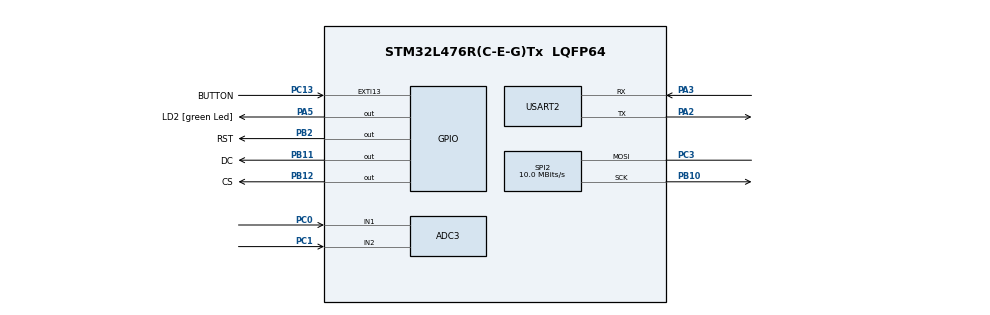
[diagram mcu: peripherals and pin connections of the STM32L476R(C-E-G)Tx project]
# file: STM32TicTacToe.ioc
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ADC3.Channel-0\#ChannelRegularConversion=ADC_CHANNEL_1
ADC3.Channel-1\#ChannelRegularConversion=ADC_CHANNEL_2
ADC3.ClockPrescaler=ADC_CLOCK_SYNC_PCLK_DIV4
ADC3.DataAlign=ADC_DATAALIGN_RIGHT
ADC3.NbrOfConversion=2
ADC3.NbrOfConversionFlag=1
ADC3.OffsetNumber-0\#ChannelRegularConversion=ADC_OFFSET_NONE
ADC3.OffsetNumber-1\#ChannelRegularConversion=ADC_OFFSET_NONE
ADC3.Rank-0\#ChannelRegularConversion=1
ADC3.Rank-1\#ChannelRegularConversion=2
ADC3.SamplingTime-0\#ChannelRegularConversion=ADC_SAMPLETIME_92CYCLES_5
ADC3.SamplingTime-1\#ChannelRegularConversion=ADC_SAMPLETIME_92CYCLES_5
Dma.Request0=SPI2_TX
Dma.SPI2_TX.0.Direction=DMA_MEMORY_TO_PERIPH
Dma.SPI2_TX.0.Instance=DMA1_Channel5
Dma.SPI2_TX.0.MemDataAlignment=DMA_MDATAALIGN_BYTE
Dma.SPI2_TX.0.MemInc=DMA_MINC_ENABLE
Dma.SPI2_TX.0.Mode=DMA_NORMAL
Dma.SPI2_TX.0.PeriphDataAlignment=DMA_PDATAALIGN_BYTE
Dma.SPI2_TX.0.PeriphInc=DMA_PINC_DISABLE
Dma.SPI2_TX.0.Priority=DMA_PRIORITY_LOW
Mcu.Family=STM32L4
Mcu.Name=STM32L476R(C-E-G)Tx
Mcu.Package=LQFP64
NVIC.DMA1_Channel5_IRQn=true\:0\:0\:false\:false\:true\:false\:true\:true
NVIC.EXTI15_10_IRQn=true\:0\:0\:false\:false\:true\:true\:true\:true
NVIC.PriorityGroup=NVIC_PRIORITYGROUP_4
PA13\ (JTMS-SWDIO).GPIO_Label=TMS
PA13\ (JTMS-SWDIO).Mode=Serial_Wire
PA13\ (JTMS-SWDIO).Signal=SYS_JTMS-SWDIO
PA14\ (JTCK-SWCLK).GPIO_Label=TCK
PA14\ (JTCK-SWCLK).Mode=Serial_Wire
PA14\ (JTCK-SWCLK).Signal=SYS_JTCK-SWCLK
PA2.Mode=Asynchronous
PA2.Signal=USART2_TX
PA3.Mode=Asynchronous
PA3.Signal=USART2_RX
PA5.GPIO_Label=LD2 [green Led]
PA5.GPIO_ModeDefaultOutputPP=GPIO_MODE_OUTPUT_PP
PA5.GPIO_PuPd=GPIO_NOPULL
PA5.GPIO_Speed=GPIO_SPEED_FREQ_LOW
PA5.Signal=GPIO_Output
PB10.Mode=Simplex_Bidirectional_Master
PB10.Signal=SPI2_SCK
PB11.GPIO_Label=DC
PB11.Signal=GPIO_Output
PB12.GPIO_Label=CS
PB12.PinState=GPIO_PIN_SET
PB12.Signal=GPIO_Output
PB2.GPIO_Label=RST
PB2.Signal=GPIO_Output
PB3\ (JTDO-TRACESWO).GPIO_Label=SWO
PB3\ (JTDO-TRACESWO).Signal=SYS_JTDO-SWO
PC0.Signal=ADCx_IN1
PC1.Signal=ADCx_IN2
PC13.GPIO_Label=BUTTON
PC13.GPIO_ModeDefaultEXTI=GPIO_MODE_IT_FALLING
PC13.GPIO_PuPd=GPIO_NOPULL
PC13.Signal=GPXTI13
PC14-OSC32_IN\ (PC14).Mode=LSE-External-Oscillator
PC14-OSC32_IN\ (PC14).Signal=RCC_OSC32_IN
PC15-OSC32_OUT\ (PC15).Mode=LSE-External-Oscillator
PC15-OSC32_OUT\ (PC15).Signal=RCC_OSC32_OUT
PC3.Mode=Simplex_Bidirectional_Master
PC3.Signal=SPI2_MOSI
PH0-OSC_IN\ (PH0).Signal=RCC_OSC_IN
PH1-OSC_OUT\ (PH1).Signal=RCC_OSC_OUT
ProjectManager.HeapSize=0x1500
ProjectManager.StackSize=0x2000
ProjectManager.TargetToolchain=STM32CubeIDE
RCC.ADCFreq_Value=64000000
RCC.AHBFreq_Value=80000000
RCC.APB1Freq_Value=80000000
RCC.APB1TimFreq_Value=80000000
RCC.APB2Freq_Value=80000000
RCC.APB2TimFreq_Value=80000000
RCC.CortexFreq_Value=80000000
RCC.HCLKFreq_Value=80000000
RCC.HSE_VALUE=8000000
RCC.HSI_VALUE=16000000
RCC.MSI_VALUE=4000000
RCC.PLLN=10
RCC.PLLSAI1Q=RCC_PLLQ_DIV4
RCC.PLLSourceVirtual=RCC_PLLSOURCE_HSI
RCC.PREFETCH_ENABLE=1
RCC.SYSCLKFreq_VALUE=80000000
RCC.SYSCLKSource=RCC_SYSCLKSOURCE_PLLCLK
RCC.USBFreq_Value=32000000
RCC.VCOOutputFreq_Value=160000000
SH.ADCx_IN1.0=ADC3_IN1,IN1-Single-Ended
SH.ADCx_IN2.0=ADC3_IN2,IN2-Single-Ended
SPI2.BaudRatePrescaler=SPI_BAUDRATEPRESCALER_8
SPI2.CalculateBaudRate=10.0 MBits/s
SPI2.DataSize=SPI_DATASIZE_8BIT
SPI2.Direction=SPI_DIRECTION_1LINE
SPI2.Mode=SPI_MODE_MASTER
SPI2.NSSPMode=SPI_NSS_PULSE_DISABLE
SPI2.VirtualType=VM_MASTER
USART2.VirtualMode-Asynchronous=VM_ASYNC
board=NUCLEO-L476RG

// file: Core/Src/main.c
/* USER CODE BEGIN Header */
/**
  ******************************************************************************
  * @file           : main.c
  * @brief          : Main program body
  ******************************************************************************
  * @attention
  *
  * Copyright (c) 2024 STMicroelectronics.
  * All rights reserved.
  *
  * This software is licensed under terms that can be found in the LICENSE file
  * in the root directory of this software component.
  * If no LICENSE file comes with this software, it is provided AS-IS.
  *
  ******************************************************************************
  */
/* USER CODE END Header */
#include "main.h"
#include "adc.h"
#include "dma.h"
#include "spi.h"
#include "usart.h"
#include "gpio.h"

/* USER CODE BEGIN Includes */
#include "../MyLibraries/ADC.h"
#include "../MyLibraries/GPIO.h"
#include "../MyLibraries/LCD.h"
#include "../MyLibraries/SPI.h"
#include "../MyLibraries/TICTACTOE.h"
#include "../MyLibraries/USART.h"
#include <stdio.h>
/* USER CODE END Includes */

void SystemClock_Config(void);

int main(void)
{

  /* MCU Configuration--------------------------------------------------------*/

  /* Reset of all peripherals, Initializes the Flash interface and the Systick. */
  LL_APB2_GRP1_EnableClock(LL_APB2_GRP1_PERIPH_SYSCFG);
  LL_APB1_GRP1_EnableClock(LL_APB1_GRP1_PERIPH_PWR);

  /* System interrupt init*/
  NVIC_SetPriorityGrouping(NVIC_PRIORITYGROUP_4);

  /* Configure the system clock */
  SystemClock_Config();

  /* Initialize all configured peripherals */
  MX_GPIO_Init();
  MX_DMA_Init();
  MX_SPI2_Init();
  MX_ADC3_Init();
  MX_USART2_UART_Init();

  /* Infinite loop */
  /* USER CODE BEGIN WHILE */
  	LL_SPI_Disable(SPI2);
    GPIO_set(1, CS_GPIO_Port, CS_Pin);

    LCDInit();
    ADCStartConversion();

    LCDCopy();

    while (1)
    {

  	  TicMain();

    /* USER CODE END WHILE */

  }
}

void SystemClock_Config(void)
{
  LL_FLASH_SetLatency(LL_FLASH_LATENCY_4);
  while(LL_FLASH_GetLatency()!= LL_FLASH_LATENCY_4)
  {
  }
  LL_PWR_SetRegulVoltageScaling(LL_PWR_REGU_VOLTAGE_SCALE1);
  while (LL_PWR_IsActiveFlag_VOS() != 0)
  {
  }
  LL_RCC_HSI_Enable();

   /* Wait till HSI is ready */
  while(LL_RCC_HSI_IsReady() != 1)
  {

  }
  LL_RCC_HSI_SetCalibTrimming(16);
  LL_RCC_PLL_ConfigDomain_SYS(LL_RCC_PLLSOURCE_HSI, LL_RCC_PLLM_DIV_1, 10, LL_RCC_PLLR_DIV_2);
  LL_RCC_PLL_EnableDomain_SYS();
  LL_RCC_PLL_Enable();

   /* Wait till PLL is ready */
  while(LL_RCC_PLL_IsReady() != 1)
  {

  }
  LL_RCC_SetSysClkSource(LL_RCC_SYS_CLKSOURCE_PLL);

   /* Wait till System clock is ready */
  while(LL_RCC_GetSysClkSource() != LL_RCC_SYS_CLKSOURCE_STATUS_PLL)
  {

  }
  LL_RCC_SetAHBPrescaler(LL_RCC_SYSCLK_DIV_1);
  LL_RCC_SetAPB1Prescaler(LL_RCC_APB1_DIV_1);
  LL_RCC_SetAPB2Prescaler(LL_RCC_APB2_DIV_1);

  LL_Init1msTick(80000000);

  LL_SetSystemCoreClock(80000000);
}

void Error_Handler(void)
{
  __disable_irq();
  while (1)
  {
  }
}
